# CY8C5888LTI_LP097 register map
File version: 0.1
CY8C58LP
Registers are 8-bit, read-write, no defined reset value unless marked. A register's access mark holds for its fields unless they carry their own. Offsets are from the block's base; lines under a group give offsets from that group; [hi:lo] are bit positions; {n}, {i} and the like mark numbered series; 'fields as' and 'values as' point back to an identical list; <NAME> marks a mode.

## Memory map
0x00000000 checkWatchDogTimer
0x00000000 SleepTimer
0x00000000 UART
0x00000000 PWM_Recon
0x00000000 Out_Comp
0x00000000 Bit_Timer

## checkWatchDogTimer
Base 0x00000000
0x400043A3 checkWatchDogTimer_GLOBAL_ENABLE — PM.ACT.CFG
  [3:0] en_timer — Enable timer/counters.
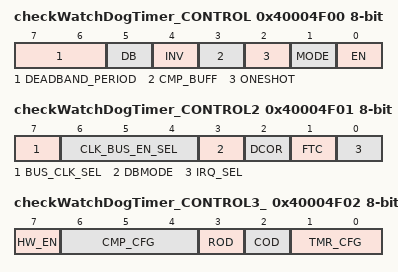
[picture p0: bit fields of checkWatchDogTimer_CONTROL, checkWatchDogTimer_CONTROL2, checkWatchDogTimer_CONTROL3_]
0x40004F00 checkWatchDogTimer_CONTROL — TMRx.CFG0
  [7:6] DEADBAND_PERIOD
  [5] DB — Deadband mode--Deadband phases phi1 and phi2 are outputted on CMP and TC output pins respectively.
    0=Timer (CMP and TC are output.); 1=Deadband (PHI1 (instead of CMP) and PHI2 (instead of TC) are output.)
  [4] INV — Invert sense of TIMEREN signal
  [3] CMP_BUFF — Buffer compare register. Compare register updates only on timer terminal count.
  [2] ONESHOT — Timer stops upon reaching stop condition defined by TMR_CFG bits. Can be restarted by asserting TIMER RESET or disabling and re-enabling block.
  [1] MODE — Mode. (0 = Timer; 1 = Comparator)
    0=Timer mode. CNT/CMP register holds timer count value.; 1=Comparator mode. CNT/CMP register holds comparator threshold value.
  [0] EN — Enables timer/comparator.
0x40004F01 checkWatchDogTimer_CONTROL2 — TMRx.CFG1
  [7] BUS_CLK_SEL — Bus Clock selection.
  [6:4] CLK_BUS_EN_SEL — Digital Global Clock selection.
  [3] DBMODE — Deadband mode (asynchronous/synchronous). CMP output pin is also affected when not in deadband mode (CFG0.DEADBAND).
  [2] DCOR — Disable Clear on Read (DCOR) of Status Register SR0.
  [1] FTC — First Terminal Count (FTC). Setting this bit forces a single pulse on the TC pin when first enabled.
    0=Disable_FTC (Disable the single cycle pulse, which signifies the timer is starting.); 1=Enable_FTC (Enable the single cycle pulse, which signifies the timer is starting.)
  [0] IRQ_SEL — Irq selection. (0 = raw interrupts; 1 = status register interrupts)
0x40004F02 checkWatchDogTimer_CONTROL3_ — TMRx.CFG2
  [7] HW_EN — When set Timer Enable controls counting.
  [6:4] CMP_CFG — Comparator configurations
    0=Equal (Compare Equal); 1=Less_than (Compare Less Than); 2=Less_than_or_equal (Compare Less Than or Equal .); 3=Greater (Compare Greater Than .); 4=Greater_than_or_equal (Compare Greater Than or Equal)
  [3] ROD — Reset On Disable (ROD). Resets internal state of output logic
  [2] COD — Clear On Disable (COD). Clears or gates outputs to zero.
  [1:0] TMR_CFG — Timer configuration (MODE = 0): 000 = Continuous; 001 = Pulsewidth; 010 = Period; 011 = Stop on IRQ
    0=Continuous (Timer runs while EN bit of CFG0 register is set to '1'.); 1=Pulsewidth (Timer runs from positive to negative edge of TIMEREN.); 2=Period (Timer runs from positive to positive edge of TIMEREN.); 3=Irq (Timer runs until IRQ.)
0x40004F04 checkWatchDogTimer_PERIOD 16-bit — TMRx.PER0 - Assigned Period
0x40004F06 checkWatchDogTimer_COUNTER 16-bit — TMRx.CNT_CMP0 - Current Down Counter Value

## SleepTimer
Base 0x00000000
0x40004381 SleepTimer_CTW_INTERVAL_REG — Timewheel Configuration Register 1
  [3:0] ctw_interval — Sets the central timewheel interval.
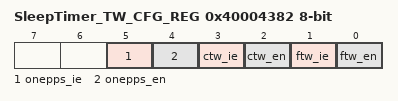
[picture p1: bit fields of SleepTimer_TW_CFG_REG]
0x40004382 SleepTimer_TW_CFG_REG — Timewheel Configuration Register 2
  [5] onepps_ie — When set and one pulse-per-second is enabled, an interrupt is issued when the pulse occurs.
    1=Enabled (One PPS interrupt is enabled); 0=Disabled (One PPS interrupt is disabled)
  [4] onepps_en — When set, the system returns to the active global power mode once every second.
    1=Enabled (One PPS is enabled); 0=Disabled (One PPS is disabled)
  [3] ctw_ie — When set and the central timewheel is enabled, an interrupt is issued when the central timewheel reaches the selected interval.
    1=Enabled (CTW interrupt is enabled); 0=Disabled (CTW interrupt is disabled)
  [2] ctw_en — When set, the system returns to the active global power mode when the central timewheel reaches the selected interval.
    1=Enabled (CTW is enabled); 0=Disabled (CTW is disabled)
  [1] ftw_ie — When set and the fast timewheel is enabled, an interrupt is issued when it reaches the terminal count.
    1=Enabled (FTW interrupt is enabled); 0=Disabled (FTW interrupt is disabled)
  [0] ftw_en — When set, the system returns to the active global power mode when the fast timewheel reaches the selected interval.
    1=Enabled (FTW is enabled); 0=Disabled (FTW is disabled)
